AUTOSAR XML (schema 4-2-2)
package /STELLANTIS/EPT/SASWCs
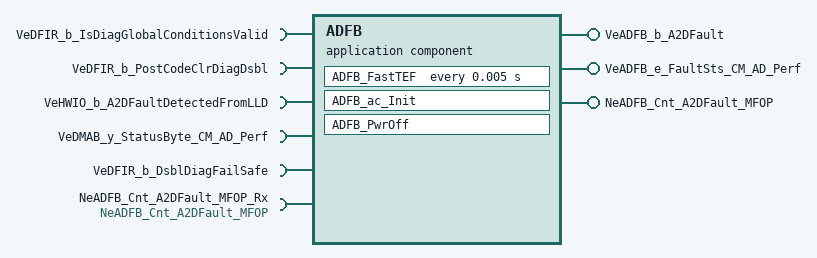
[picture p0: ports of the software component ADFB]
  application sw component type ADFB
    5 x require port, all with nonqueued-receiver-com-spec{data-element=Value, init-value=0}:
      VeDFIR_b_IsDiagGlobalConditionsValid: required-interface=VeDFIR_b_IsDiagGlobalConditionsValid
      VeDFIR_b_PostCodeClrDiagDsbl: required-interface=VeDFIR_b_PostCodeClrDiagDsbl
      VeHWIO_b_A2DFaultDetectedFromLLD: required-interface=VeHWIO_b_A2DFaultDetectedFromLLD
      VeDMAB_y_StatusByte_CM_AD_Perf: required-interface=VeDMAB_y_StatusByte_CM_AD_Perf
      VeDFIR_b_DsblDiagFailSafe: required-interface=VeDFIR_b_DsblDiagFailSafe
    provide port VeADFB_b_A2DFault: nonqueued-sender-com-spec{data-element=Value, init-value=0}, provided-interface=VeADFB_b_A2DFault
    provide port VeADFB_e_FaultSts_CM_AD_Perf: nonqueued-sender-com-spec{data-element=Value, init-value=CeDFIB_e_Init}, provided-interface=VeADFB_e_FaultSts_CM_AD_Perf
    require port NeADFB_Cnt_A2DFault_MFOP_Rx: nv-require-com-spec{init-value=0, variable=NeADFB_Cnt_A2DFault_MFOP}, required-interface=NeADFB_Cnt_A2DFault_MFOP
    provide port NeADFB_Cnt_A2DFault_MFOP: nv-provide-com-spec{ram-block-init-value=0, variable=NeADFB_Cnt_A2DFault_MFOP}, provided-interface=NeADFB_Cnt_A2DFault_MFOP
    behavior IB_ADFB: data-type-mapping=msADTtoIDTMapping, handle-termination-and-restart=NO-SUPPORT
      timing event Event_FastTEF: start-on-event=ADFB_FastTEF, period=0.005
      init event Event_ADFB_ac_Init: start-on-event=ADFB_ac_Init
      init event Event_PwrOff: start-on-event=ADFB_PwrOff
      runnable ADFB_ac_Init
        data-receive-point-by-arguments:
          access IN_NeADFB_Cnt_A2DFault_MFOP_Rx_NeADFB_Cnt_A2DFault_MFOP: accessed-variable=NeADFB_Cnt_A2DFault_MFOP_Rx.NeADFB_Cnt_A2DFault_MFOP
        data-send-points:
          access OUT_VeADFB_e_FaultSts_CM_AD_Perf_Value: accessed-variable=VeADFB_e_FaultSts_CM_AD_Perf.Value
      runnable ADFB_FastTEF
        data-receive-point-by-arguments:
          5 x access:
            IN_VeDFIR_b_DsblDiagFailSafe_Value: accessed-variable=VeDFIR_b_DsblDiagFailSafe.Value
            IN_VeDFIR_b_IsDiagGlobalConditionsValid_Value: accessed-variable=VeDFIR_b_IsDiagGlobalConditionsValid.Value
            IN_VeDFIR_b_PostCodeClrDiagDsbl_Value: accessed-variable=VeDFIR_b_PostCodeClrDiagDsbl.Value
            IN_VeDMAB_y_StatusByte_CM_AD_Perf_Value: accessed-variable=VeDMAB_y_StatusByte_CM_AD_Perf.Value
            IN_VeHWIO_b_A2DFaultDetectedFromLLD_Value: accessed-variable=VeHWIO_b_A2DFaultDetectedFromLLD.Value
        data-send-points:
          access OUT_VeADFB_b_A2DFault_Value: accessed-variable=VeADFB_b_A2DFault.Value
          access OUT_VeADFB_e_FaultSts_CM_AD_Perf_Value: accessed-variable=VeADFB_e_FaultSts_CM_AD_Perf.Value
      runnable ADFB_PwrOff
        data-send-points:
          access OUT_NeADFB_Cnt_A2DFault_MFOP_NeADFB_Cnt_A2DFault_MFOP: accessed-variable=NeADFB_Cnt_A2DFault_MFOP.NeADFB_Cnt_A2DFault_MFOP
